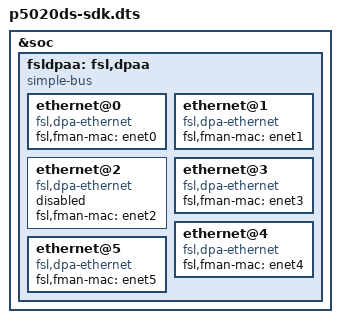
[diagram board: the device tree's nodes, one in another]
// SPDX-License-Identifier: (GPL-2.0+ OR BSD-3-Clause)
/*
 * Copyright 2017-2018 NXP
 */

/include/ "p5020ds.dts"

/include/ "qoriq-fman-0-sdk.dtsi"
/include/ "qoriq-bman-portals-sdk.dtsi"
/include/ "qoriq-qman1-portals-sdk.dtsi"

&soc {
	fsldpaa: fsl,dpaa {
		compatible = "simple-bus", "fsl,dpaa";
		ethernet@0 {
			compatible = "fsl,dpa-ethernet";
			fsl,fman-mac = <&enet0>;
		};
		ethernet@1 {
			compatible = "fsl,dpa-ethernet";
			fsl,fman-mac = <&enet1>;
		};
		ethernet@2 {
			compatible = "fsl,dpa-ethernet";
			fsl,fman-mac = <&enet2>;
			status = "disabled";
		};
		ethernet@3 {
			compatible = "fsl,dpa-ethernet";
			fsl,fman-mac = <&enet3>;
		};
		ethernet@4 {
			compatible = "fsl,dpa-ethernet";
			fsl,fman-mac = <&enet4>;
		};
		ethernet@5 {
			compatible = "fsl,dpa-ethernet";
			fsl,fman-mac = <&enet5>;
		};
	};
};
